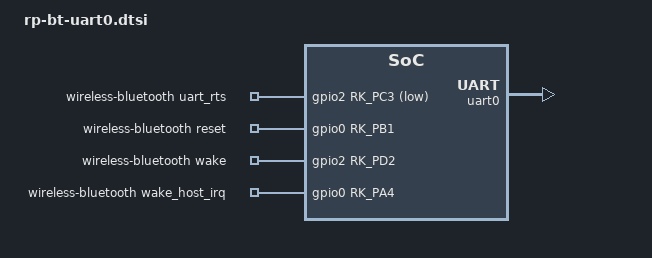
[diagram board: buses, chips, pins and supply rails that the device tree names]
/ {
    wireless-bluetooth {
        compatible = "bluetooth-platdata";
        clocks = <&rk808 1>;
        clock-names = "ext_clock";
        //wifi-bt-power-toggle;
        uart_rts_gpios = <&gpio2 RK_PC3 GPIO_ACTIVE_LOW>; /* GPIO2_C3 */
        pinctrl-names = "default", "rts_gpio";
        pinctrl-0 = <&uart0_rts>, <&bt_reset_gpio>, <&bt_wake_gpio>, <&bt_irq_gpio>;
        pinctrl-1 = <&uart0_gpios>;
        //BT,power_gpio  = <&gpio3 19 GPIO_ACTIVE_HIGH>; /* GPIOx_xx */
        BT,reset_gpio    = <&gpio0 RK_PB1 GPIO_ACTIVE_HIGH>; /* GPIO0_B1 */
        BT,wake_gpio     = <&gpio2 RK_PD2 GPIO_ACTIVE_HIGH>; /* GPIO2_D2 */
        BT,wake_host_irq = <&gpio0 RK_PA4 GPIO_ACTIVE_HIGH>; /* GPIO0_A4 */
        status = "okay";
    };

};

&uart0 {
    pinctrl-names = "default";
    pinctrl-0 = <&uart0_xfer &uart0_cts>;
    status = "okay";
};

&pinctrl {
    wireless-bluetooth {
        uart0_gpios: uart0-gpios {
            rockchip,pins =
                <2 RK_PC3 RK_FUNC_GPIO &pcfg_pull_none>;
        };
        bt_reset_gpio: bt-reset-gpio {
            rockchip,pins =
                <0 RK_PB1 RK_FUNC_GPIO &pcfg_pull_none>;
        };
        bt_wake_gpio: bt-wake-gpio {
            rockchip,pins =
                <2 RK_PD2 RK_FUNC_GPIO &pcfg_pull_none>;
        };
        bt_irq_gpio: bt-irq-gpio {
            rockchip,pins =
                <0 RK_PA4 RK_FUNC_GPIO &pcfg_pull_down>;
        };
    };
};
